VERSION ""

NS_ :

BS_:

BU_: HANDCART BMS_HV HANDCART BMS_HV HANDCART BMS_HV BMS_HV HANDCART HANDCART BMS_HV CELLBOARD HANDCART MAINBOARD BMS_HV MAINBOARD HANDCART CELLBOARD BMS_HV CELLBOARD HANDCART MAINBOARD BMS_HV MAINBOARD HANDCART CELLBOARD BMS_HV MAINBOARD HANDCART CELLBOARD BMS_HV MAINBOARD HANDCART CELLBOARD BMS_HV HANDCART BMS_HV

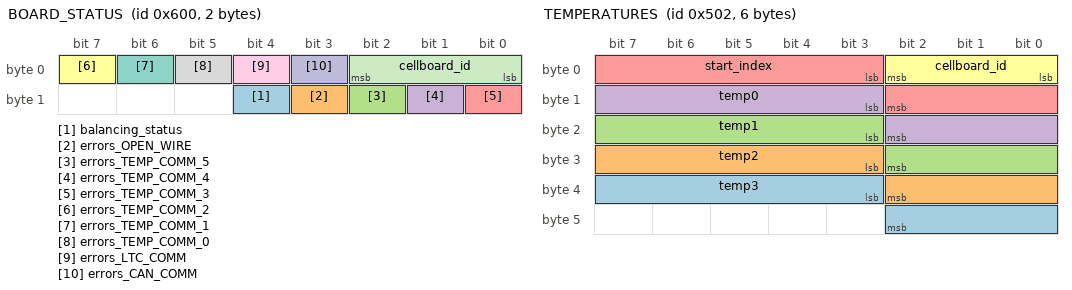
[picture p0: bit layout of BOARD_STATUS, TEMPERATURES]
BO_ 1536 BOARD_STATUS: 2 Vector__XXX
 SG_ balancing_status : 12|1@1+ (1,0) [0|1] "" Vector__XXX
 SG_ errors_OPEN_WIRE : 11|1@1+ (1,0) [0|1] "" Vector__XXX
 SG_ errors_TEMP_COMM_5 : 10|1@1+ (1,0) [0|1] "" Vector__XXX
 SG_ errors_TEMP_COMM_4 : 9|1@1+ (1,0) [0|1] "" Vector__XXX
 SG_ errors_TEMP_COMM_3 : 8|1@1+ (1,0) [0|1] "" Vector__XXX
 SG_ errors_TEMP_COMM_2 : 7|1@1+ (1,0) [0|1] "" Vector__XXX
 SG_ errors_TEMP_COMM_1 : 6|1@1+ (1,0) [0|1] "" Vector__XXX
 SG_ errors_TEMP_COMM_0 : 5|1@1+ (1,0) [0|1] "" Vector__XXX
 SG_ errors_LTC_COMM : 4|1@1+ (1,0) [0|1] "" Vector__XXX
 SG_ errors_CAN_COMM : 3|1@1+ (1,0) [0|1] "" Vector__XXX
 SG_ cellboard_id : 0|3@1+ (1,0) [0|7] "" Vector__XXX

BO_ 1282 TEMPERATURES: 6 Vector__XXX
 SG_ temp3 : 35|8@1+ (0.39215686274509803,-20) [-20|80] "" Vector__XXX
 SG_ temp2 : 27|8@1+ (0.39215686274509803,-20) [-20|80] "" Vector__XXX
 SG_ temp1 : 19|8@1+ (0.39215686274509803,-20) [-20|80] "" Vector__XXX
 SG_ temp0 : 11|8@1+ (0.39215686274509803,-20) [-20|80] "" Vector__XXX
 SG_ start_index : 3|8@1+ (1,0) [0|255] "" Vector__XXX
 SG_ cellboard_id : 0|3@1+ (1,0) [0|7] "" Vector__XXX

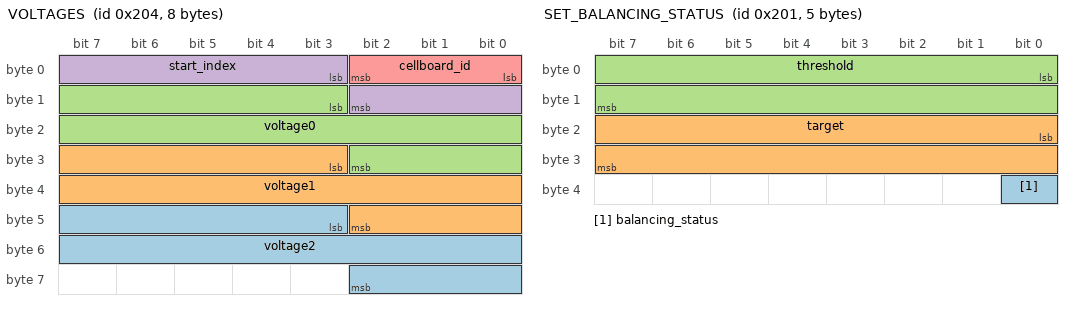
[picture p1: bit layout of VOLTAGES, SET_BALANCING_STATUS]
BO_ 516 VOLTAGES: 8 Vector__XXX
 SG_ voltage2 : 43|16@1+ (7.629510948348211e-05,0) [0|5] "" Vector__XXX
 SG_ voltage1 : 27|16@1+ (7.629510948348211e-05,0) [0|5] "" Vector__XXX
 SG_ voltage0 : 11|16@1+ (7.629510948348211e-05,0) [0|5] "" Vector__XXX
 SG_ start_index : 3|8@1+ (1,0) [0|255] "" Vector__XXX
 SG_ cellboard_id : 0|3@1+ (1,0) [0|7] "" Vector__XXX

BO_ 513 SET_BALANCING_STATUS: 5 Vector__XXX
 SG_ balancing_status : 32|1@1+ (1,0) [0|1] "" Vector__XXX
 SG_ target : 16|16@1+ (1,0) [0|65535] "" Vector__XXX
 SG_ threshold : 0|16@1+ (1,0) [0|65535] "" Vector__XXX

BO_ 515 BALANCING_STATUS: 1 Vector__XXX
 SG_ balancing_status : 0|1@1+ (1,0) [0|1] "" Vector__XXX

BO_ 0 JMP_TO_BLT: 2 Vector__XXX
 SG_ board_index : 3|8@1+ (1,0) [0|255] "" Vector__XXX
 SG_ cellboard_id : 0|3@1+ (1,0) [0|7] "" Vector__XXX

BO_ 4 FLASH_CELLBOARD_0_TX: 0 Vector__XXX

BO_ 5 FLASH_CELLBOARD_0_RX: 0 Vector__XXX

BO_ 6 FLASH_CELLBOARD_1_TX: 0 Vector__XXX

BO_ 7 FLASH_CELLBOARD_1_RX: 0 Vector__XXX

BO_ 8 FLASH_CELLBOARD_2_TX: 0 Vector__XXX

BO_ 9 FLASH_CELLBOARD_2_RX: 0 Vector__XXX

BO_ 10 FLASH_CELLBOARD_3_TX: 0 Vector__XXX

BO_ 11 FLASH_CELLBOARD_3_RX: 0 Vector__XXX

BO_ 12 FLASH_CELLBOARD_4_TX: 0 Vector__XXX

BO_ 13 FLASH_CELLBOARD_4_RX: 0 Vector__XXX

BO_ 14 FLASH_CELLBOARD_5_TX: 0 Vector__XXX

BO_ 15 FLASH_CELLBOARD_5_RX: 0 Vector__XXX

CM_ BO_ 1536 "Cellboard's status";
CM_ BO_ 1282 "Cells' temperatures";
CM_ BO_ 516 "Cells' voltages";
CM_ BO_ 513 "Set balancing status for cells";
CM_ BO_ 515 "Discharging status";
CM_ BO_ 0 "Starts firmware update";

VAL_ 1536 balancing_status 0 "OFF" 1 "DISCHARGE" ;
VAL_ 1536 cellboard_id 0 "CELLBOARD_0" 1 "CELLBOARD_1" 2 "CELLBOARD_2" 3 "CELLBOARD_3" 4 "CELLBOARD_4" 5 "CELLBOARD_5" ;
VAL_ 1282 cellboard_id 0 "CELLBOARD_0" 1 "CELLBOARD_1" 2 "CELLBOARD_2" 3 "CELLBOARD_3" 4 "CELLBOARD_4" 5 "CELLBOARD_5" ;
VAL_ 516 cellboard_id 0 "CELLBOARD_0" 1 "CELLBOARD_1" 2 "CELLBOARD_2" 3 "CELLBOARD_3" 4 "CELLBOARD_4" 5 "CELLBOARD_5" ;
VAL_ 513 balancing_status 0 "OFF" 1 "DISCHARGE" ;
VAL_ 515 balancing_status 0 "OFF" 1 "DISCHARGE" ;
VAL_ 0 cellboard_id 0 "CELLBOARD_0" 1 "CELLBOARD_1" 2 "CELLBOARD_2" 3 "CELLBOARD_3" 4 "CELLBOARD_4" 5 "CELLBOARD_5" ;
